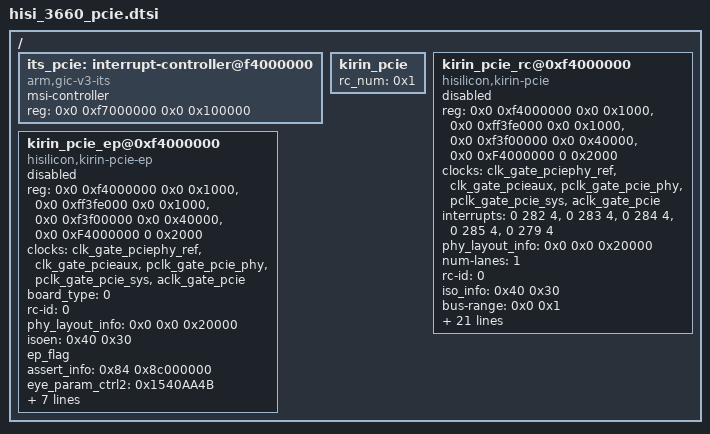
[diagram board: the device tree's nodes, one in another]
/**
 * Note: any file.dtsi or node in this file will be compile into all config.dts
 *so, if your node or file.dtsi will not use on some products, please don't put it here
 */

/{
    its_pcie: interrupt-controller@f4000000 {
		compatible = "arm,gic-v3-its";
		msi-controller;
		reg = <0x0 0xf7000000 0x0 0x100000>;
	};

	kirin_pcie {
		rc_num = <0x1>;
	};

	kirin_pcie_rc@0xf4000000 {
		compatible = "hisilicon,kirin-pcie";
		reg =  <0x0 0xf4000000 0x0 0x1000>, <0x0 0xff3fe000 0x0 0x1000>, <0x0 0xf3f00000 0x0 0x40000>, <0x0 0xF4000000 0 0x2000>;
		reg-names = "dbi","apb","phy", "config";
		clocks = <&clk_gate_pciephy_ref>, <&clk_gate_pcieaux>, <&pclk_gate_pcie_phy>, <&pclk_gate_pcie_sys>, <&aclk_gate_pcie>;
		clock-names = "pcie_phy_ref", "pcie_aux", "pcie_apb_phy", "pcie_apb_sys", "pcie_aclk";
		interrupts = <0 282 4>, <0 283 4>, <0 284 4>, <0 285 4>, <0 279 4>;
		interrupt-names = "INTa", "INTb", "INTc", "INTd", "link_down";
		#address-cells = <3>;
		#size-cells = <2>;
		device_type = "pci";
		ranges = <0x02000000 0x0 0xf5000000 0x0 0xf5000000 0x0 0x02000000>;
		/* natural_phy_offset sram_phy_offset apb_phy_offset*/
		phy_layout_info = <0x0 0x0 0x20000>;
		num-lanes = <1>;
		rc-id = <0>;
		iso_info = <0x40 0x30>;
		bus-range = <0x0  0x1>;
		msi-parent = <&its_pcie>;
		#interrupt-cells = <1>;
		interrupt-map-mask = <0 0 0 7>;
		interrupt-map = <0 0 0 1 &gic 0 0 0 282 4>,
				<0 0 0 2 &gic 0 0 0  283 4>,
				<0 0 0 3 &gic 0 0 0  284 4>,
				<0 0 0 4 &gic 0 0 0  285 4>;
		pinctrl-names = "default", "idle";
		pinctrl-0 = <&gpio089_pmx_func &gpio089_cfg_func>;
		pinctrl-1 = <&gpio089_pmx_idle &gpio089_cfg_idle>;
		reset-gpio = <&gpio11 1 0 >;
		assert_info = <0x84 0x8c000000>;
		eye_param_ctrl2 = <0x1540AA4B>;
		eye_param_ctrl3 = <0x14003FFF>;
		ep_ltr_latency = <0x10031003>;
		ep_l1ss_ctrl2 = <0x61>;
		l1ss_ctrl1 = <0x4004370F>;
		aspm_state = <0x2>;
		iatu_base_offset = <0x900>;
		num-viewport = <16>;
		t_ref2perst = <21000 23000>;
		t_perst2access = <7000 8000>;
		t_perst2rst = <10000 11000>;

		/* NOC Target ID, for pcie dump mntn when PCIe NOC happens*/
		noc_target_id = <0x1A>;
		status = "disabled";
	};

	kirin_pcie_ep@0xf4000000 {
		compatible = "hisilicon,kirin-pcie-ep";
		reg =  <0x0 0xf4000000 0x0 0x1000>, <0x0 0xff3fe000 0x0 0x1000>, <0x0 0xf3f00000 0x0 0x40000>, <0x0 0xF4000000 0 0x2000>;
		reg-names = "dbi","apb","phy", "config";
		clocks =  <&clk_gate_pciephy_ref>, <&clk_gate_pcieaux>, <&pclk_gate_pcie_phy>, <&pclk_gate_pcie_sys>, <&aclk_gate_pcie>;
		clock-names = "pcie_phy_ref", "pcie_aux", "pcie_apb_phy", "pcie_apb_sys", "pcie_aclk";
		board_type = <0>;
		rc-id = <0>;
		/* natural_phy_offset sram_phy_offset apb_phy_offset*/
		phy_layout_info = <0x0 0x0 0x20000>;
		isoen = <0x40 0x30>;
		ep_flag;
		device_type = "pci";
		assert_info = <0x84 0x8c000000>;
		eye_param_ctrl2 = <0x1540AA4B>;
		eye_param_ctrl3 = <0x14003FFF>;
		pinctrl-names = "default", "idle";
		pinctrl-0 = <&gpio089_pmx_func &gpio089_cfg_func>;
		pinctrl-1 = <&gpio089_pmx_idle &gpio089_cfg_idle>;
		reset-gpio = <&gpio11 1 0 >;
		iatu_base_offset = <0x900>;
		/* NOC Target ID, for pcie dump mntn when PCIe NOC happens*/
		noc_target_id = <0x1A>;
		num-viewport = <16>;
		status = "disabled";
	};
};
